# R7FA6E10F register map
Vendor: Renesas Electronics Corporation; Series: RA6; File version: 1.20.00
CPU: CM33 r0p4, little endian, MPU, FPU, VTOR, 4 interrupt priority bits, 96 interrupts
Registers are 8-bit, read-write, reset 0x0 unless marked. A register's access mark holds for its fields unless they carry their own. Offsets are from the block's base; [hi:lo] are bit positions; {n}, {i} and the like mark numbered series; 'fields as' and 'values as' point back to an identical list.

## TZF — TrustZone Filter
Base 0x40000E00
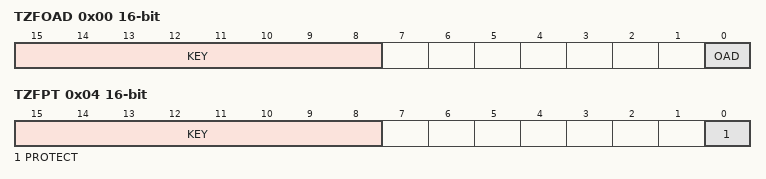
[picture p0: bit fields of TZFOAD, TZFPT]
0x00 TZFOAD 16-bit — TrustZone Filter Operation After Detection Register
  [15:8] KEY wo — KeyCode
  [0] OAD — Operation after detection
    0=Non-maskable interrupt; 1=Reset
0x04 TZFPT 16-bit — TrustZone Filter Protect Register
  [15:8] KEY wo — KeyCode
  [0] PROTECT — Protection of register
    0=All Bus TrustZone Filter register writing is protected. Read is possible.; 1=All Bus TrustZone Filter register writing is possible

## SRAM — SRAM Control
Base 0x40002000
0x00 PARIOAD — SRAM Parity Error Operation After Detection Register
  [0] OAD — Operation After Detection
    0=Non-maskable interrupt; 1=Reset
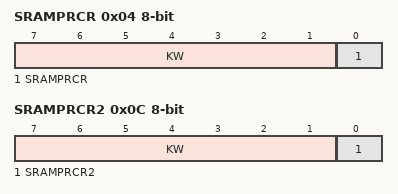
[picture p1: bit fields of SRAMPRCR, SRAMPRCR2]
0x04 SRAMPRCR — SRAM Protection Register
  [7:1] KW wo — Write Key Code
  [0] SRAMPRCR — Register Write Control
    0=Disable writes to protected registers; 1=Enable writes to protected registers
0x08 SRAMWTSC reset 0x1 — SRAM Wait State Control Register
  [0] SRAM0WTEN — SRAM0 wait enable
    0=No wait; 1=Add wait state in read access cycle to SRAM0
0x0C SRAMPRCR2 — SRAM Protection Register 2
  [7:1] KW wo — Write Key Code
  [0] SRAMPRCR2 — Register Write Control
    0=Disable writes to the protected registers; 1=Enable writes to the protected registers

## BUS — Bus Control
Base 0x40003000
0x1100 BUSSCNTFHBIU 16-bit — Slave Bus Control Register
  [1:0] ARBS — Arbitration Select for three masters
    0=EDMAC > DMAC/DTC > CPU; 1=Setting prohibited; 2=(EDMAC ↔ DMAC/DTC) > CPU; 3=(EDMAC ↔ DMAC/DTC) ↔ CPU
0x1104 BUSSCNTFLBIU 16-bit — Slave Bus Control Register
  fields as BUSSCNTFHBIU
0x1110 BUSSCNTS0BIU 16-bit — Slave Bus Control Register
  fields as BUSSCNTFHBIU
0x1120 BUSSCNTPSBIU 16-bit — Slave Bus Control Register
  [0] ARBS — Arbitration Select for two masters
    0=DMAC/DTC > CPU; 1=DMAC/DTC ↔ CPU
0x1130 BUSSCNTPLBIU 16-bit — Slave Bus Control Register
  fields as BUSSCNTPSBIU
0x1134 BUSSCNTPHBIU 16-bit — Slave Bus Control Register
  fields as BUSSCNTPSBIU
0x1140 BUSSCNTEQBIU 16-bit — Slave Bus Control Register
  fields as BUSSCNTFHBIU
{0x17F0+0x10*i} BUS{i}ERRADD (i=1..4) 32-bit ro — BUS Error Address Register
  [31:0] BERAD — Bus Error Address
{0x17F4+0x10*i} BUS{i}ERRRW (i=1..4) — BUS Error Read Write Register
  [0] RWSTAT ro — Error Access Read/Write Status
    0=Read access; 1=Write access
{0x18F0+0x10*i} BTZF{i}ERRADD (i=1..4) 32-bit ro — BUS TZF Error Address Register
  [31:0] BTZFERAD — Bus TrustZone Filter Error Address
{0x18F4+0x10*i} BTZF{i}ERRRW (i=1..4) — BUS TZF Error Read Write Register
  [0] TRWSTAT ro — TrustZone filter error access Read/Write Status
    0=Read access; 1=Write access
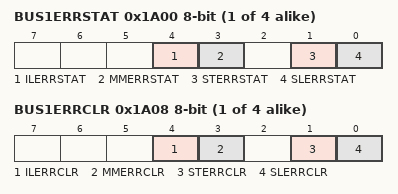
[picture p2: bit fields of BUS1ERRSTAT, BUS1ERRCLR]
{0x19F0+0x10*i} BUS{i}ERRSTAT (i=1..4) ro — BUS Error Status Register {i}
  [all] fields
    0=No error occurred; 1=Error occurred
  [4] ILERRSTAT — Illegal address access Error Status
  [3] MMERRSTAT — Master MPU Error Status
  [1] STERRSTAT — Slave TrustZone filter Error Status
  [0] SLERRSTAT — Slave bus Error Status
{0x19F8+0x10*i} BUS{i}ERRCLR (i=1..4) — BUS Error Clear Register {i}
  [4] ILERRCLR — Illegal Address Access Error Clear
  [3] MMERRCLR — Master MPU Error Clear
  [1] STERRCLR — Slave TrustZone filter Error Clear
  [0] SLERRCLR — Slave bus Error Clear
0x1A24 DMACDTCERRSTAT ro — DMAC/DTC Error Status Register
  [0] MTERRSTAT — Master TrustZone Filter Error Status
    0=No error occurred; 1=Error occurred
0x1A2C DMACDTCERRCLR — DMAC/DTC Error Clear Register
  [0] MTERRCLR — Master TrustZone filter Error Clear

## DMA — DMAC Module Activation
Base 0x40005200
0x00 DMAST — DMA Module Activation Register
  [0] DMST — DMAC Operation Enable
    0=DMAC activation is disabled; 1=DMAC activation is enabled
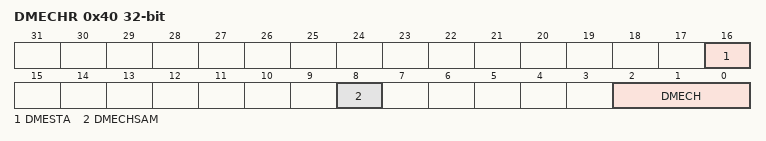
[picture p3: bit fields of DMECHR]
0x40 DMECHR 32-bit — DMAC Error Channel Register
  [16] DMESTA — DMAC Error Status
    0=No DMA transfer error occurred; 1=DMA transfer error occurred
  [8] DMECHSAM ro — DMAC Error channel Security Attribution Monitor
    0=Secure channel; 1=Non-secure channel
  [2:0] DMECH ro — DMAC Error channel

## Notices in the file
This software is supplied by Renesas Electronics Corporation and is only intended for
use with Renesas products. No other uses are authorized. This software is owned by
Renesas Electronics Corporation and is protected under all applicable laws, including
copyright laws.
THIS SOFTWARE IS PROVIDED "AS IS" AND RENESAS MAKES NO WARRANTIES REGARDING
THIS SOFTWARE, WHETHER EXPRESS, IMPLIED OR STATUTORY, INCLUDING BUT NOT LIMITED TO
WARRANTIES OF MERCHANTABILITY, FITNESS FOR A PARTICULAR PURPOSE AND NON-INFRINGEMENT.
ALL SUCH WARRANTIES ARE EXPRESSLY DISCLAIMED. TO THE MAXIMUM EXTENT PERMITTED NOT
PROHIBITED BY LAW, NEITHER RENESAS ELECTRONICS CORPORATION NOR ANY OF ITS AFFILIATED
COMPANIES SHALL BE LIABLE FOR ANY DIRECT, INDIRECT, SPECIAL, INCIDENTAL OR CONSEQUENTIAL
DAMAGES FOR ANY REASON RELATED TO THIS SOFTWARE, EVEN IF RENESAS OR ITS AFFILIATES HAVE
BEEN ADVISED OF THE POSSIBILITY OF SUCH DAMAGES.
Renesas reserves the right, without notice, to make changes to this software and to
discontinue the availability of this software. By using this software, you agree to
the additional terms and conditions found by accessing the following link:
http://www.renesas.com/disclaimer
